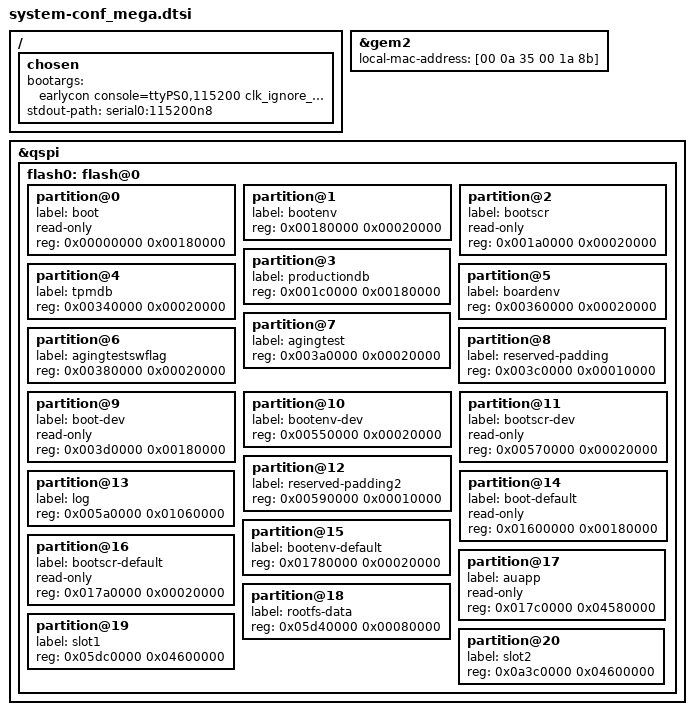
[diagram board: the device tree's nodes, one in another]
/*
 * CAUTION: This file is automatically generated by PetaLinux SDK.
 * DO NOT modify this file
 */


/ {
	chosen {
		bootargs = " earlycon console=ttyPS0,115200 clk_ignore_unused uio_pdrv_genirq.of_id=generic-uio root=/dev/ram0 rw";
		stdout-path = "serial0:115200n8";
	};
};

&gem2 {
	local-mac-address = [00 0a 35 00 1a 8b];
};

&qspi {
	#address-cells = <1>;
	#size-cells = <0>;
	flash0: flash@0 {
		/delete-node/ partition@0;
		/delete-node/ partition@100000;
		/delete-node/ partition@600000;
		/delete-node/ partition@620000;
		partition@0 {
			label = "boot";
                        read-only;
			reg = <0x00000000 0x00180000>;
		};
		partition@1 {
			label = "bootenv";
			reg = <0x00180000 0x00020000>;
		};
		partition@2 {
			label = "bootscr";
                        read-only;
			reg = <0x001a0000 0x00020000>;
		};
		partition@3 {
			label = "productiondb";
			reg = <0x001c0000 0x00180000>;
		};
		partition@4 {
			label = "tpmdb";
			reg = <0x00340000 0x00020000>;
		};
		partition@5 {
			label = "boardenv";
			reg = <0x00360000 0x00020000>;
		};
		partition@6 {
			label = "agingtestswflag";
			reg = <0x00380000 0x00020000>;
		};
		partition@7 {
			label = "agingtest";
			reg = <0x003a0000 0x00020000>;
		};
		partition@8 {
			label = "reserved-padding";
			reg = <0x003c0000 0x00010000>;
		};
		partition@9 {
			label = "boot-dev";
                        read-only;
			reg = <0x003d0000 0x00180000>;
		};
		partition@10 {
			label = "bootenv-dev";
			reg = <0x00550000 0x00020000>;
		};
		partition@11 {
			label = "bootscr-dev";
                        read-only;
			reg = <0x00570000 0x00020000>;
		};
		partition@12 {
			label = "reserved-padding2";
			reg = <0x00590000 0x00010000>;
		};
		partition@13 {
			label = "log";
			reg = <0x005a0000 0x01060000>;
		};
		partition@14 {
			label = "boot-default";
                        read-only;
			reg = <0x01600000 0x00180000>;
		};
		partition@15 {
			label = "bootenv-default";
			reg = <0x01780000 0x00020000>;
		};
		partition@16 {
			label = "bootscr-default";
                        read-only;
			reg = <0x017a0000 0x00020000>;
		};
		partition@17 {
			label = "auapp";
                        read-only;
			reg = <0x017c0000 0x04580000>;
		};
		partition@18 {
			label = "rootfs-data";
			reg = <0x05d40000 0x00080000>;
		};		
		partition@19 {
			label = "slot1";
			reg = <0x05dc0000 0x04600000>;
		};
		partition@20 {
			label = "slot2";
			reg = <0x0a3c0000 0x04600000>;
		};
	};
};

